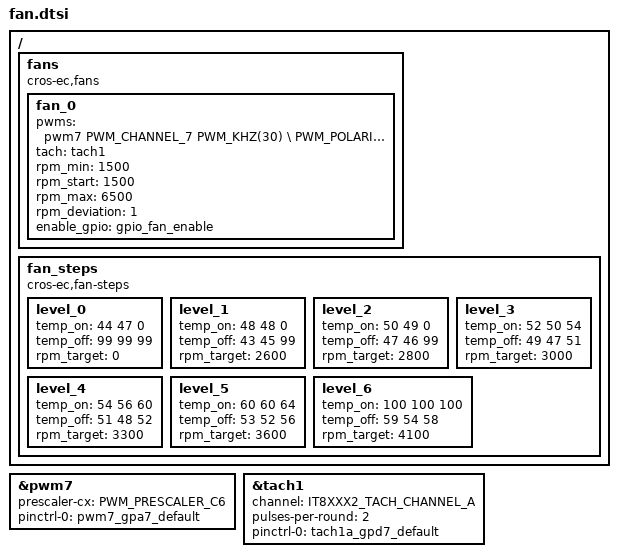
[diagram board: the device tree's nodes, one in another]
/* Copyright 2023 The ChromiumOS Authors
 * Use of this source code is governed by a BSD-style license that can be
 * found in the LICENSE file.
 */
/ {
	fans {
		compatible = "cros-ec,fans";
		fan_0 {
			pwms = <&pwm7 PWM_CHANNEL_7 PWM_KHZ(30) \
				PWM_POLARITY_NORMAL>;
			tach = <&tach1>;
			rpm_min = <1500>;
			rpm_start = <1500>;
			rpm_max = <6500>;
			rpm_deviation = <1>;
			enable_gpio = <&gpio_fan_enable>;
		};
	};
	fan_steps {
		compatible = "cros-ec,fan-steps";
		level_0 {
			temp_on = <44 47 0>;
			temp_off = <99 99 99>;
			rpm_target = <0>;
		};
		level_1 {
			temp_on = <48 48 0>;
			temp_off = <43 45 99>;
			rpm_target = <2600>;
		};
		level_2 {
			temp_on = <50 49 0>;
			temp_off = <47 46 99>;
			rpm_target = <2800>;
		};
		level_3 {
			temp_on = <52 50 54>;
			temp_off = <49 47 51>;
			rpm_target = <3000>;
		};
		level_4 {
			temp_on = <54 56 60>;
			temp_off = <51 48 52>;
			rpm_target = <3300>;
		};
		level_5 {
			temp_on = <60 60 64>;
			temp_off = <53 52 56>;
			rpm_target = <3600>;
		};
		level_6 {
			temp_on = <100 100 100>;
			temp_off = <59 54 58>;
			rpm_target = <4100>;
		};
	};
};

/* pwm for fan */
&pwm7 {
	status = "okay";
	prescaler-cx = <PWM_PRESCALER_C6>;
	pinctrl-0 = <&pwm7_gpa7_default>;
	pinctrl-names = "default";
};

/* fan tachometer sensor */
&tach1 {
	status = "okay";
	channel = <IT8XXX2_TACH_CHANNEL_A>;
	pulses-per-round = <2>;
	pinctrl-0 = <&tach1a_gpd7_default>;
	pinctrl-names = "default";
};
